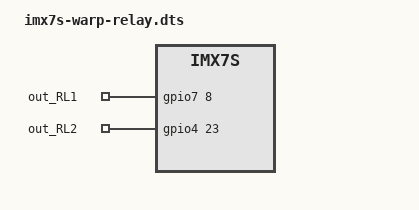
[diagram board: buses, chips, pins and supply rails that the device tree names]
#include "imx7s-warp.dts"

/ {
	gpio_exporter: gpio-exporter {
		compatible = "linux,gpio-exporter";	
		pinctrl-names = "default";
		pinctrl-0 = <&pinctrl_gpioexporter_relay>;
	
		out_RL1 {
			gpios = <&gpio7 8 GPIO_ACTIVE_HIGH>;
			output;
			initial-state = <0>;
		};
		
		out_RL2 {
			gpios = <&gpio4 23 GPIO_ACTIVE_HIGH>;
			output;
			initial-state = <0>;
		};
	};
};

&iomuxc {
	pinctrl-names = "default";
	imx7s-warp {
		
		pinctrl_gpioexporter_relay: gpioexportergrp {
			fsl,pins = <
				MX7D_PAD_ENET1_RGMII_TD2__GPIO7_IO8        0x14
				MX7D_PAD_ECSPI2_SS0__GPIO4_IO23	   0x14 
			>;
		};
	};
};
